# WS63 register map
File version: 1.0
CPU: other r0p0, little endian, MPU, FPU, 3 interrupt priority bits
Registers are 32-bit, read-write, reset 0x0 unless marked. A register's access mark holds for its fields unless they carry their own. Offsets are from the block's base; [hi:lo] are bit positions; {n}, {i} and the like mark numbered series.

## TSENSOR — Temperature sensor controller (v151)
Base 0x4400E000
0x00 TSENSOR_CTL_ID — Temperature sensor control ID
  [15:0] tsensor_ctl_id ro — Control ID
{0x10+4i} TSENSOR_REG{i} (i=0..3) — Common register {i}
  [31:0] tsensor_reg{i} — Common configuration register {i}
0x300 TSENSOR_START — Temperature sensor start register
  [0] tsensor_start wo — Write 1 to refresh temperature reading
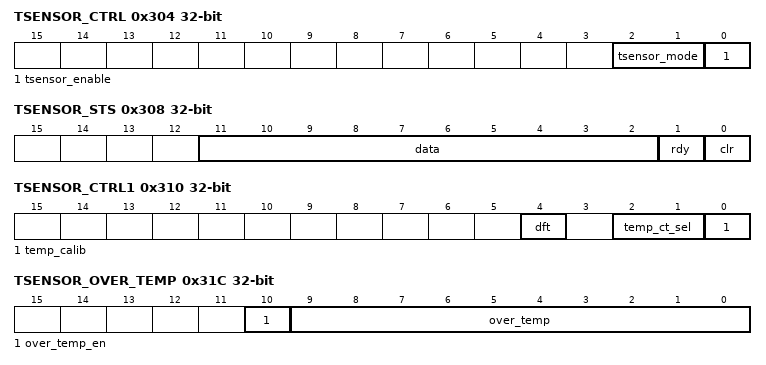
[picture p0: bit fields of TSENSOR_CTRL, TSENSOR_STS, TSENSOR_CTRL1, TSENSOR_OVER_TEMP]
0x304 TSENSOR_CTRL — Temperature sensor control register
  [2:1] tsensor_mode — Temperature sensor mode
  [0] tsensor_enable — Temperature sensor enable
0x308 TSENSOR_STS — Temperature sensor status register
  [11:2] data ro — Temperature code (10-bit, range 114-896 for -40C to 125C)
  [1] rdy ro — Data ready flag
  [0] clr — Clear status
0x310 TSENSOR_CTRL1 — Temperature sensor control 1
  [4] dft — DFT mode enable
  [2:1] temp_ct_sel — Temperature CT select
  [0] temp_calib — Temperature calibration enable
0x314 TSENSOR_TEMP_HIGH_LIMIT — High temperature limit
  [9:0] temp_high_limit — High temperature threshold (10-bit code)
0x318 TSENSOR_TEMP_LOW_LIMIT — Low temperature limit
  [9:0] temp_low_limit — Low temperature threshold (10-bit code)
0x31C TSENSOR_OVER_TEMP — Over-temperature threshold
  [10] over_temp_en — Over-temperature interrupt enable
  [9:0] over_temp — Over-temperature threshold (10-bit code)
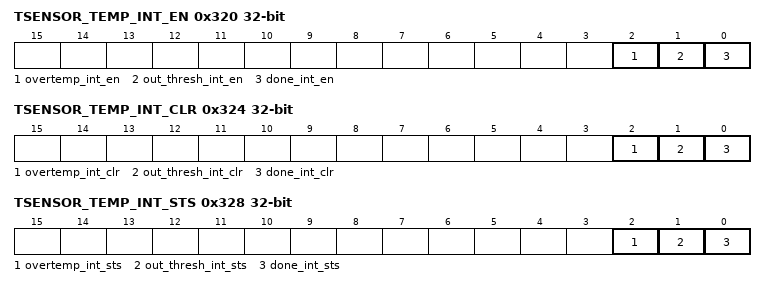
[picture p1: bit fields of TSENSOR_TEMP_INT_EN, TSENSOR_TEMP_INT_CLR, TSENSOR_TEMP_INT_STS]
0x320 TSENSOR_TEMP_INT_EN — Temperature interrupt enable
  [2] overtemp_int_en — Over-temperature interrupt enable
  [1] out_thresh_int_en — Out-of-threshold interrupt enable
  [0] done_int_en — Conversion done interrupt enable
0x324 TSENSOR_TEMP_INT_CLR — Temperature interrupt clear
  [2] overtemp_int_clr wo — Clear over-temperature interrupt
  [1] out_thresh_int_clr wo — Clear out-of-threshold interrupt
  [0] done_int_clr wo — Clear done interrupt
0x328 TSENSOR_TEMP_INT_STS — Temperature interrupt status
  [2] overtemp_int_sts ro — Over-temperature interrupt status
  [1] out_thresh_int_sts ro — Out-of-threshold interrupt status
  [0] done_int_sts ro — Conversion done interrupt status
0x330 TSENSOR_AUTO_REFRESH_PERIOD — Auto refresh period
  [15:0] auto_refresh_period — Auto refresh period in 32kHz clock cycles
0x334 TSENSOR_AUTO_REFRESH_CFG — Auto refresh configuration
  [0] auto_refresh_en — Auto refresh enable

## TIMER — Timer module with 3 independent 32-bit timers (v150)
Base 0x44002000
0x60 ABNOR_INTR_RAW — Abnormal interrupt raw status
  [2:0] abnor_intr_raw ro — Abnormal interrupt raw status for all timers
0x64 ABNOR_IMSK — Abnormal interrupt mask
  [2:0] abnor_imsk — Abnormal interrupt mask for all timers
0x68 ABNOR_INTR_STAT — Abnormal interrupt status
  [2:0] abnor_intr_stat ro — Abnormal interrupt status for all timers
0x78 EOI_REN wo — End-of-interrupt register
  [2:0] eoi — Clear interrupts for all timers by writing one bit per channel; reads return zero and do not clear on WS63 silicon
0x7C RAW_INTR_STAT — Raw interrupt status
  [2:0] raw_intr ro — Raw interrupt status for all timers
0x80 INTR_STAT — Interrupt status (masked)
  [2:0] intr_stat ro — Interrupt status for all timers (after mask)
{0x100+0x100*i} TIMER{i}_LOAD_COUNT (i=0..2) — Timer {i} [dim=3] load count
  [31:0] load_count — Timer 0 load count value
{0x108+0x100*i} TIMER{i}_CURRENT_VALUE (i=0..2) — Timer {i} [dim=3] current value
  [31:0] current_value ro — Timer 0 current count value
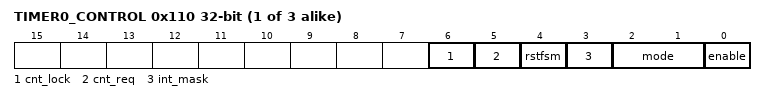
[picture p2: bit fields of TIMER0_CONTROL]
{0x110+0x100*i} TIMER{i}_CONTROL (i=0..2) — Timer {i} [dim=3] control register
  [6] cnt_lock ro — Current-count latch valid (TIMER_V150): set by HW after a cnt_req snapshot completes; poll until 1 before reading the current-value register.
  [5] cnt_req — Current-count latch request (TIMER_V150): write 1 to snapshot the live down-counter into the current-value register; the HW asserts cnt_lock when the snapshot is ready. Required to read a fresh count on silicon (the current-value register is a latch, not a live counter).
  [4] rstfsm wo — Reset FSM: 1=reset timer FSM
  [3] int_mask — Interrupt mask: 0=unmasked; 1=masked
  [2:1] mode — Timer mode (TIMER_V150, per vendor control_reg_mode_v150_t): 0=one-shot; 1=periodic; 3=free-run (2 is a one-shot alias)
    0=One-shot mode; 1=Periodic mode; 3=Free-running mode
  [0] enable — Timer enable: 0=disabled; 1=enabled
{0x114+0x100*i} TIMER{i}_EOI (i=0..2) wo — Timer {i} [dim=3] end-of-interrupt
  [0] eoi — Write 1 to clear this timer interrupt; reads return zero and do not clear on WS63 silicon
{0x118+0x100*i} TIMER{i}_RAW_INTR (i=0..2) — Timer {i} [dim=3] raw interrupt status
  [0] raw_intr ro — Raw interrupt status
